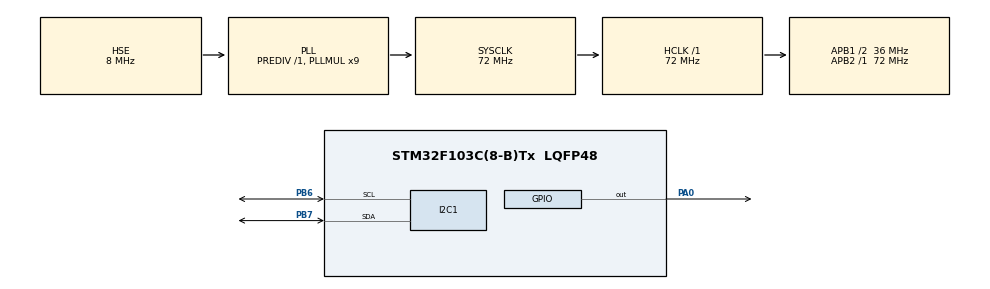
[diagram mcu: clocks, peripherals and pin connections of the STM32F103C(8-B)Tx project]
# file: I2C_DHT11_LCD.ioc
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Mcu.Family=STM32F1
Mcu.Name=STM32F103C(8-B)Tx
Mcu.Package=LQFP48
NVIC.PriorityGroup=NVIC_PRIORITYGROUP_4
PA0-WKUP.Signal=GPIO_Output
PA13.Mode=Serial_Wire
PA13.Signal=SYS_JTMS-SWDIO
PA14.Mode=Serial_Wire
PA14.Signal=SYS_JTCK-SWCLK
PB6.Mode=I2C
PB6.Signal=I2C1_SCL
PB7.Mode=I2C
PB7.Signal=I2C1_SDA
PD0-OSC_IN.Mode=HSE-External-Oscillator
PD0-OSC_IN.Signal=RCC_OSC_IN
PD1-OSC_OUT.Mode=HSE-External-Oscillator
PD1-OSC_OUT.Signal=RCC_OSC_OUT
ProjectManager.HeapSize=0x200
ProjectManager.StackSize=0x400
ProjectManager.TargetToolchain=STM32CubeIDE
RCC.AHBFreq_Value=72000000
RCC.APB1CLKDivider=RCC_HCLK_DIV2
RCC.APB1Freq_Value=36000000
RCC.APB1TimFreq_Value=72000000
RCC.APB2Freq_Value=72000000
RCC.APB2TimFreq_Value=72000000
RCC.HCLKFreq_Value=72000000
RCC.PLLMUL=RCC_PLL_MUL9
RCC.PLLSourceVirtual=RCC_PLLSOURCE_HSE
RCC.SYSCLKFreq_VALUE=72000000
RCC.SYSCLKSource=RCC_SYSCLKSOURCE_PLLCLK
RCC.USBFreq_Value=72000000
TIM2.Period=0xFFFF
TIM2.Prescaler=71
VP_TIM2_VS_ClockSourceINT.Mode=Internal
board=custom

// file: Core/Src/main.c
/* USER CODE BEGIN Header */
/**
  ******************************************************************************
  * @file           : main.c
  * @brief          : Main program body
  ******************************************************************************
  * @attention
  *
  * Copyright (c) 2023 STMicroelectronics.
  * All rights reserved.
  *
  * This software is licensed under terms that can be found in the LICENSE file
  * in the root directory of this software component.
  * If no LICENSE file comes with this software, it is provided AS-IS.
  *
  ******************************************************************************
  */
/* USER CODE END Header */
#include "main.h"

/* USER CODE BEGIN Includes */
#include "i2c-lcd.h"
#include "stdio.h"
/* USER CODE END Includes */

I2C_HandleTypeDef hi2c1;

TIM_HandleTypeDef htim2;

void SystemClock_Config(void);
static void MX_GPIO_Init(void);
static void MX_I2C1_Init(void);
static void MX_TIM2_Init(void);

/* USER CODE BEGIN 0 */
void delay(unsigned int time){
	HAL_TIM_Base_Start(&htim2);
	__HAL_TIM_SET_COUNTER(&htim2, 0);
	while((__HAL_TIM_GET_COUNTER(&htim2)) < time);
	HAL_TIM_Base_Stop(&htim2);
}

void Display_Temp (int Temp)
{
	char str[20] = {0};
	lcd_put_cur(0, 1);

	sprintf (str, "NHIET DO:- %d ", Temp);
	lcd_send_string(str);
	lcd_send_data('C');
}

void Display_Rh (int Rh)
{
	char str[20] = {0};
	lcd_put_cur(1, 1);

	sprintf (str, "DO AM:- %d ", Rh);
	lcd_send_string(str);
	lcd_send_data('%');
}

uint8_t Rh_byte1, Rh_byte2, Temp_byte1, Temp_byte2;
uint16_t SUM, RH, TEMP;

int Temperature = 0;
int Humidity = 0;
uint8_t Presence = 0;

/*****************************DHT11 function***************************/

#define DHT11_PORT GPIOA
#define DHT11_PIN GPIO_PIN_0
/* USER CODE END 0 */

void DHT11_Start (void)
{

	HAL_GPIO_WritePin (DHT11_PORT, DHT11_PIN, 0);   // pull the pin low
	delay (20000);  // wait for >18ms
    HAL_GPIO_WritePin (DHT11_PORT, DHT11_PIN, 1);   // pull the pin high
	delay (45);   // wait for 40us, đợi DHT11 respone
}

uint8_t DHT11_Check_Response (void)
{
	uint8_t Response = 0;
	if (!(HAL_GPIO_ReadPin (DHT11_PORT, DHT11_PIN)))
	{
		delay (80);
		if ((HAL_GPIO_ReadPin (DHT11_PORT, DHT11_PIN))) Response = 1; // đã sẵn dàng gửi data
		else Response = -1; // 255, chưa sẵn sàng để gửi data
	}
	while ((HAL_GPIO_ReadPin (DHT11_PORT, DHT11_PIN)));   // wait for the pin to go low

	return Response;
}

uint8_t DHT11_Read (void)
{
	uint8_t i,j;
	for (j=0;j<8;j++)
	{
		while (!(HAL_GPIO_ReadPin (DHT11_PORT, DHT11_PIN)));   // wait for the pin to go high
		delay (40);   // wait for 40 us
		if (!(HAL_GPIO_ReadPin (DHT11_PORT, DHT11_PIN)))   // if the pin is low
		{
			i&= ~(1<<(7-j));   // write 0, giữ các bit trước không bị thay đổi
		}
		else i|= (1<<(7-j));  // if the pin is high, write 1
		while ((HAL_GPIO_ReadPin (DHT11_PORT, DHT11_PIN)));  // wait for the pin to go low
	}
	return i;
}
int main(void)
{

  /* MCU Configuration--------------------------------------------------------*/

  /* Reset of all peripherals, Initializes the Flash interface and the Systick. */
  HAL_Init();

  /* Configure the system clock */
  SystemClock_Config();

  /* Initialize all configured peripherals */
  MX_GPIO_Init();
  MX_I2C1_Init();
  MX_TIM2_Init();
  /* USER CODE BEGIN 2 */
  lcd_init();
  lcd_put_cur(0, 1);
  lcd_send_string("KIM TUAN KIEN");
  lcd_put_cur(1, 5);
  lcd_send_string("PTIT");
  HAL_Delay(4000);
  lcd_clear();

  /* USER CODE END 2 */

  /* Infinite loop */
  while (1)
  {
	Display_Temp(Temperature);
	Display_Rh(Humidity);

	DHT11_Start();
	Presence = DHT11_Check_Response(); // co the kiem tra xem DHT11 co response k
	Rh_byte1 = DHT11_Read ();
	Rh_byte2 = DHT11_Read ();
	Temp_byte1 = DHT11_Read ();
	Temp_byte2 = DHT11_Read ();
	SUM = DHT11_Read();

	Temperature = Temp_byte1;
	Humidity = Rh_byte1;
    /* USER CODE BEGIN 3 */
	HAL_Delay(3000);
  }
  /* USER CODE END 3 */
}

void SystemClock_Config(void)
{
  RCC_OscInitTypeDef RCC_OscInitStruct = {0};
  RCC_ClkInitTypeDef RCC_ClkInitStruct = {0};

  /** Initializes the RCC Oscillators according to the specified parameters
  * in the RCC_OscInitTypeDef structure.
  */
  RCC_OscInitStruct.OscillatorType = RCC_OSCILLATORTYPE_HSE;
  RCC_OscInitStruct.HSEState = RCC_HSE_ON;
  RCC_OscInitStruct.HSEPredivValue = RCC_HSE_PREDIV_DIV1;
  RCC_OscInitStruct.HSIState = RCC_HSI_ON;
  RCC_OscInitStruct.PLL.PLLState = RCC_PLL_ON;
  RCC_OscInitStruct.PLL.PLLSource = RCC_PLLSOURCE_HSE;
  RCC_OscInitStruct.PLL.PLLMUL = RCC_PLL_MUL9;
  if (HAL_RCC_OscConfig(&RCC_OscInitStruct) != HAL_OK)
  {
    Error_Handler();
  }

  /** Initializes the CPU, AHB and APB buses clocks
  */
  RCC_ClkInitStruct.ClockType = RCC_CLOCKTYPE_HCLK|RCC_CLOCKTYPE_SYSCLK
                              |RCC_CLOCKTYPE_PCLK1|RCC_CLOCKTYPE_PCLK2;
  RCC_ClkInitStruct.SYSCLKSource = RCC_SYSCLKSOURCE_PLLCLK;
  RCC_ClkInitStruct.AHBCLKDivider = RCC_SYSCLK_DIV1;
  RCC_ClkInitStruct.APB1CLKDivider = RCC_HCLK_DIV2;
  RCC_ClkInitStruct.APB2CLKDivider = RCC_HCLK_DIV1;

  if (HAL_RCC_ClockConfig(&RCC_ClkInitStruct, FLASH_LATENCY_2) != HAL_OK)
  {
    Error_Handler();
  }
}

static void MX_I2C1_Init(void)
{

  hi2c1.Instance = I2C1;
  hi2c1.Init.ClockSpeed = 100000;
  hi2c1.Init.DutyCycle = I2C_DUTYCYCLE_2;
  hi2c1.Init.OwnAddress1 = 0;
  hi2c1.Init.AddressingMode = I2C_ADDRESSINGMODE_7BIT;
  hi2c1.Init.DualAddressMode = I2C_DUALADDRESS_DISABLE;
  hi2c1.Init.OwnAddress2 = 0;
  hi2c1.Init.GeneralCallMode = I2C_GENERALCALL_DISABLE;
  hi2c1.Init.NoStretchMode = I2C_NOSTRETCH_DISABLE;
  if (HAL_I2C_Init(&hi2c1) != HAL_OK)
  {
    Error_Handler();
  }

}

static void MX_TIM2_Init(void)
{

  TIM_ClockConfigTypeDef sClockSourceConfig = {0};
  TIM_MasterConfigTypeDef sMasterConfig = {0};

  htim2.Instance = TIM2;
  htim2.Init.Prescaler = 71;
  htim2.Init.CounterMode = TIM_COUNTERMODE_UP;
  htim2.Init.Period = 0xFFFF;
  htim2.Init.ClockDivision = TIM_CLOCKDIVISION_DIV1;
  htim2.Init.AutoReloadPreload = TIM_AUTORELOAD_PRELOAD_DISABLE;
  if (HAL_TIM_Base_Init(&htim2) != HAL_OK)
  {
    Error_Handler();
  }
  sClockSourceConfig.ClockSource = TIM_CLOCKSOURCE_INTERNAL;
  if (HAL_TIM_ConfigClockSource(&htim2, &sClockSourceConfig) != HAL_OK)
  {
    Error_Handler();
  }
  sMasterConfig.MasterOutputTrigger = TIM_TRGO_RESET;
  sMasterConfig.MasterSlaveMode = TIM_MASTERSLAVEMODE_DISABLE;
  if (HAL_TIMEx_MasterConfigSynchronization(&htim2, &sMasterConfig) != HAL_OK)
  {
    Error_Handler();
  }

}

static void MX_GPIO_Init(void)
{
  GPIO_InitTypeDef GPIO_InitStruct = {0};

  /* GPIO Ports Clock Enable */
  __HAL_RCC_GPIOD_CLK_ENABLE();
  __HAL_RCC_GPIOA_CLK_ENABLE();
  __HAL_RCC_GPIOB_CLK_ENABLE();

  /*Configure GPIO pin Output Level */
  HAL_GPIO_WritePin(GPIOA, GPIO_PIN_0, 1);

  /*Configure GPIO pin : PA0 */
  GPIO_InitStruct.Pin = GPIO_PIN_0;
  GPIO_InitStruct.Mode = GPIO_MODE_OUTPUT_OD;
  GPIO_InitStruct.Pull = GPIO_NOPULL;
  GPIO_InitStruct.Speed = GPIO_SPEED_FREQ_LOW;
  HAL_GPIO_Init(GPIOA, &GPIO_InitStruct);

}

void Error_Handler(void)
{
  __disable_irq();
  while (1)
  {
  }
}
